VERSION ""

NS_ :

BS_:
BU_: ECM BCM
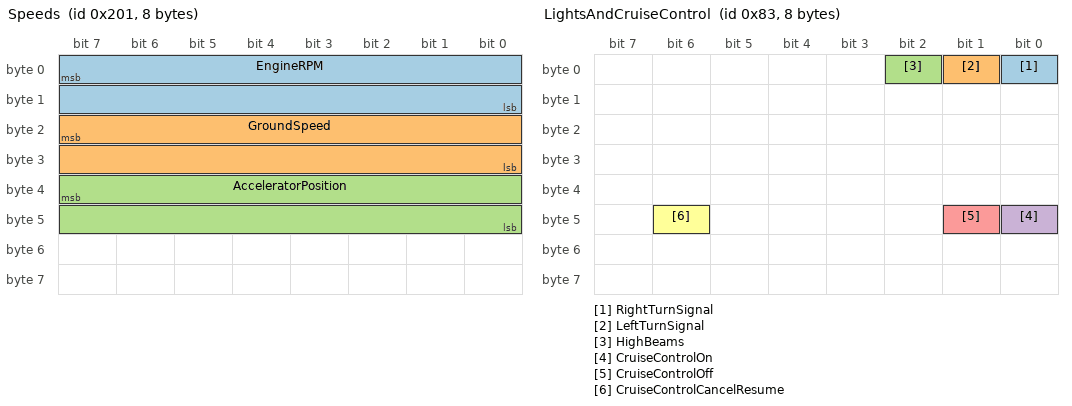
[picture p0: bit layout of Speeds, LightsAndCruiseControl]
BO_ 513 Speeds: 8 ECM
   SG_ EngineRPM : 7|16@0+ (0.25,0) [0|1] "rpm" Vector__XXX
   SG_ GroundSpeed : 23|16@0+ (0.008,0) [0|1] "mph" Vector__XXX
   SG_ AcceleratorPosition : 39|16@0+ (1,0) [0|1] "%" Vector__XXX

BO_ 131 LightsAndCruiseControl: 8 BCM
   SG_ RightTurnSignal : 0|1@0+ (1,0) [0|1] "" Vector__XXX
   SG_ LeftTurnSignal : 1|1@0+ (1,0) [0|1] "" Vector__XXX
   SG_ HighBeams : 2|1@0+ (1,0) [0|1] "" Vector__XXX
   SG_ CruiseControlOn : 40|1@0+ (1,0) [0|1] "" Vector__XXX
   SG_ CruiseControlOff : 41|1@0+ (1,0) [0|1] "" Vector__XXX
   SG_ CruiseControlCancelResume : 46|1@0+ (1,0) [0|1] "" Vector__XXX

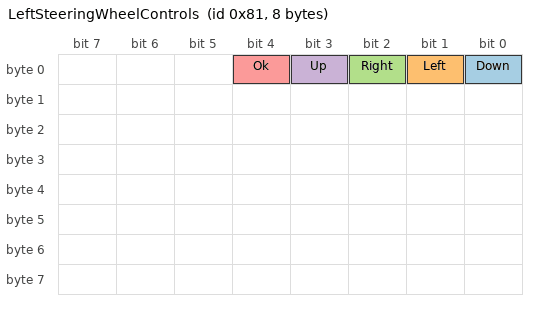
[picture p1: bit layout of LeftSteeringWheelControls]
BO_ 129 LeftSteeringWheelControls: 8 BCM
   SG_ Down : 0|1@0+ (1,0) [0|1] "" Vector__XXX
   SG_ Left : 1|1@0+ (1,0) [0|1] "" Vector__XXX
   SG_ Right : 2|1@0+ (1,0) [0|1] "" Vector__XXX
   SG_ Up : 3|1@0+ (1,0) [0|1] "" Vector__XXX
   SG_ Ok : 4|1@0+ (1,0) [0|1] "" Vector__XXX

BO_ 124 BrakePedal: 8 Vector__XXX
   SG_ BrakeTorqueRequested : 7|13@0+ (1,0) [0|1] "Nm" Vector__XXX

BA_DEF_ BO_ "GenMsgBackgroundColor" STRING ;
BA_DEF_ BO_ "GenMsgForegroundColor" STRING ;
BA_DEF_ BO_ "filterlabeling" INT 0 0;
BA_DEF_DEF_ "GenMsgBackgroundColor" "#ffffff";
BA_DEF_DEF_ "GenMsgForegroundColor" "#000000";
BA_DEF_DEF_ "filterlabeling" 1;
VAL_ 131 RightTurnSignal 1 "RightTurnSignal";
VAL_ 131 LeftTurnSignal 1 "LeftTurnSignal";
VAL_ 131 HighBeams 1 "HighBeams";
